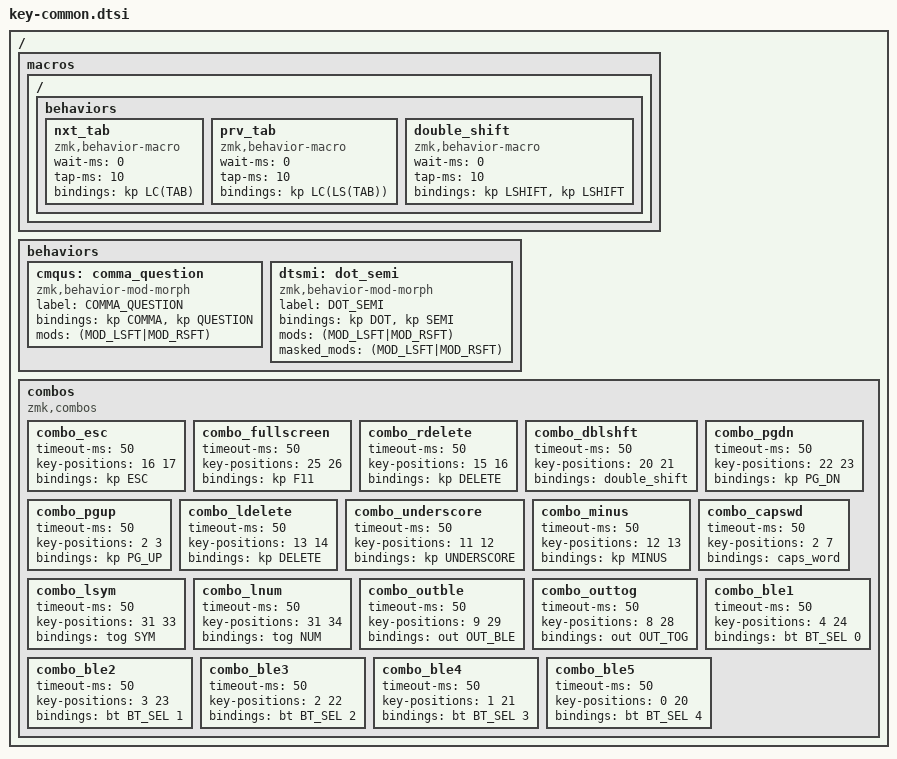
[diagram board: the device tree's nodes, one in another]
#define DEFAULT 0
#define QWERT   1
#define NUM     2
#define SYM     3

/ {
    // macros
    macros {
      ZMK_MACRO(hello, // hello world
        wait-ms = <0>;
        tap-ms  = <10>;
        bindings = <&kp LS(H) &kp E &kp L &kp L &kp O>
        , <&kp COMMA>
        , <&kp W &kp O &kp R &kp L &kp D &kp EXCL>;
      )

      ZMK_MACRO(encoder, // for encoder switch press
        wait-ms = <0>;
        tap-ms  = <10>;
        bindings = <&kp LS(I) &kp SPACE &kp A &kp M &kp SPACE &kp A &kp SPACE>
        , <&kp E &kp N &kp C &kp O &kp D &kp E &kp R>;
      )

      ZMK_MACRO(nxt_tab,
        wait-ms = <0>;
        tap-ms  = <10>;
        bindings = <&kp LC(TAB)>;
      )

      ZMK_MACRO(prv_tab,
        wait-ms = <0>;
        tap-ms  = <10>;
        bindings = <&kp LC(LS(TAB))>;
      )

      ZMK_MACRO(double_shift,
        wait-ms = <0>;
        tap-ms  = <10>;
        bindings = <&kp LSHIFT &kp LSHIFT>;
      )
    };
   
    // custom shift using mod-morph 
    behaviors {
      cmqus: comma_question {
        compatible = "zmk,behavior-mod-morph";
        label = "COMMA_QUESTION";
        #binding-cells = <0>;
        bindings = <&kp COMMA>, <&kp QUESTION>;
        mods = <(MOD_LSFT|MOD_RSFT)>;
      };

      dtsmi: dot_semi {
        compatible = "zmk,behavior-mod-morph";
        label = "DOT_SEMI";
        #binding-cells = <0>;
        bindings = <&kp DOT>, <&kp SEMI>;
        mods = <(MOD_LSFT|MOD_RSFT)>;
        masked_mods = <(MOD_LSFT|MOD_RSFT)>; // don't send shift
      };
    };

    // combos
    combos {
        compatible = "zmk,combos";
        // right hand 
        combo_esc {
            timeout-ms = <50>;
            key-positions = <16 17>;
            bindings = <&kp ESC>;
        };
        
        combo_fullscreen {
            timeout-ms = <50>;
            key-positions = <25 26>;
            bindings = <&kp F11>;
        };
        
        combo_rdelete {
            timeout-ms = <50>;
            key-positions = <15 16>;
            bindings = <&kp DELETE>;
        };
 
        // left hand
        combo_dblshft {
            timeout-ms = <50>;
            key-positions = <20 21>;
            bindings = <&double_shift>;
        };

        combo_pgdn {
            timeout-ms = <50>;
            key-positions = <22 23>;
            bindings = <&kp PG_DN>;
        };
 
        combo_pgup {
            timeout-ms = <50>;
            key-positions = <2 3>;
            bindings = <&kp PG_UP>;
        };

        combo_ldelete {
            timeout-ms = <50>;
            key-positions = <13 14>;
            bindings = <&kp DELETE>;
        };

        // symbols
        combo_underscore {
            timeout-ms = <50>;
            key-positions = <11 12>;
            bindings = <&kp UNDERSCORE>;
        };

        combo_minus {
            timeout-ms = <50>;
            key-positions = <12 13>;
            bindings = <&kp MINUS>;
        };

        // toggles
        combo_capswd {
            timeout-ms = <50>;
            key-positions = <2 7>;
            bindings = <&caps_word>;
        };

        combo_lsym {
            timeout-ms = <50>;
            key-positions = <31 33>;
            bindings = <&tog SYM>;
        };

        combo_lnum {
            timeout-ms = <50>;
            key-positions = <31 34>;
            bindings = <&tog NUM>;
        };

        // output selection
        combo_outble {
            timeout-ms = <50>;
            key-positions = <9 29>;
            bindings = <&out OUT_BLE>;
        };

        combo_outtog {
            timeout-ms = <50>;
            key-positions = <8 28>;
            bindings = <&out OUT_TOG>;
        };

        // ble selection
        combo_ble1 {
            timeout-ms = <50>;
            key-positions = <4 24>;
            bindings = <&bt BT_SEL 0>;
        };

        combo_ble2 {
            timeout-ms = <50>;
            key-positions = <3 23>;
            bindings = <&bt BT_SEL 1>;
        };

        combo_ble3 {
            timeout-ms = <50>;
            key-positions = <2 22>;
            bindings = <&bt BT_SEL 2>;
        };

        combo_ble4 {
            timeout-ms = <50>;
            key-positions = <1 21>;
            bindings = <&bt BT_SEL 3>;
        };

        combo_ble5 {
            timeout-ms = <50>;
            key-positions = <0 20>;
            bindings = <&bt BT_SEL 4>;
        };
    };
};
